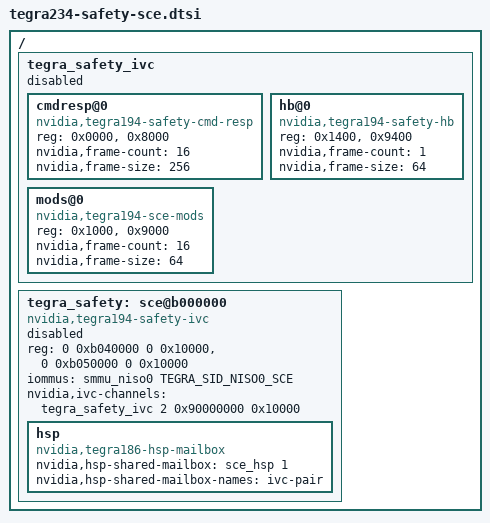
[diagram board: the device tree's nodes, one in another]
/*
 * Copyright (c) 2018-2021, NVIDIA CORPORATION.  All rights reserved.
 *
 * This program is free software; you can redistribute it and/or modify it
 * under the terms and conditions of the GNU General Public License,
 * version 2, as published by the Free Software Foundation.
 *
 * This program is distributed in the hope it will be useful, but WITHOUT
 * ANY WARRANTY; without even the implied warranty of MERCHANTABILITY or
 * FITNESS FOR A PARTICULAR PURPOSE.  See the GNU General Public License for
 * more details.
 *
 * You should have received a copy of the GNU General Public License
 * along with this program.  If not, see <http://www.gnu.org/licenses/>.
 */

/*
 * tegra194-safety-sce.dtsi: Safety SCE DTSI file.
 */

/ {
	tegra_safety_ivc: tegra_safety_ivc {
		#address-cells = <1>;
		#size-cells = <0>;
		status = "disabled";

		cmdresp@0 {
			compatible = "nvidia,tegra194-safety-cmd-resp";
			reg = <0x0000>, <0x8000>;
			reg-names = "rx", "tx";
			nvidia,frame-count = <16>;
			nvidia,frame-size = <256>;
		};

		hb@0 {
			compatible = "nvidia,tegra194-safety-hb";
			reg = <0x1400>, <0x9400>;
			reg-names = "rx", "tx";
			nvidia,frame-count = <1>;
			nvidia,frame-size = <64>;
		};

		mods@0 {
			compatible = "nvidia,tegra194-sce-mods";
			reg = <0x1000>, <0x9000>;
			reg-names = "rx", "tx";
			nvidia,frame-count = <16>;
			nvidia,frame-size = <64>;
		};

	};

	tegra_safety: sce@b000000 {
		compatible = "nvidia,tegra194-safety-ivc";
		status = "disabled";

		reg =	<0 0xb040000 0 0x10000>,
			<0 0xb050000 0 0x10000>;
		reg-names = "ast-cpu", "ast-dma";

		iommus = <&smmu_niso0 TEGRA_SID_NISO0_SCE>;
		/* This property contains ast-region-id, IOVA, ast-region-size */
		nvidia,ivc-channels = <&tegra_safety_ivc 2 0x90000000 0x10000>;

		hsp {
			compatible = "nvidia,tegra186-hsp-mailbox";
			nvidia,hsp-shared-mailbox = <&sce_hsp 1>;
			nvidia,hsp-shared-mailbox-names = "ivc-pair";
		};
	};
};
